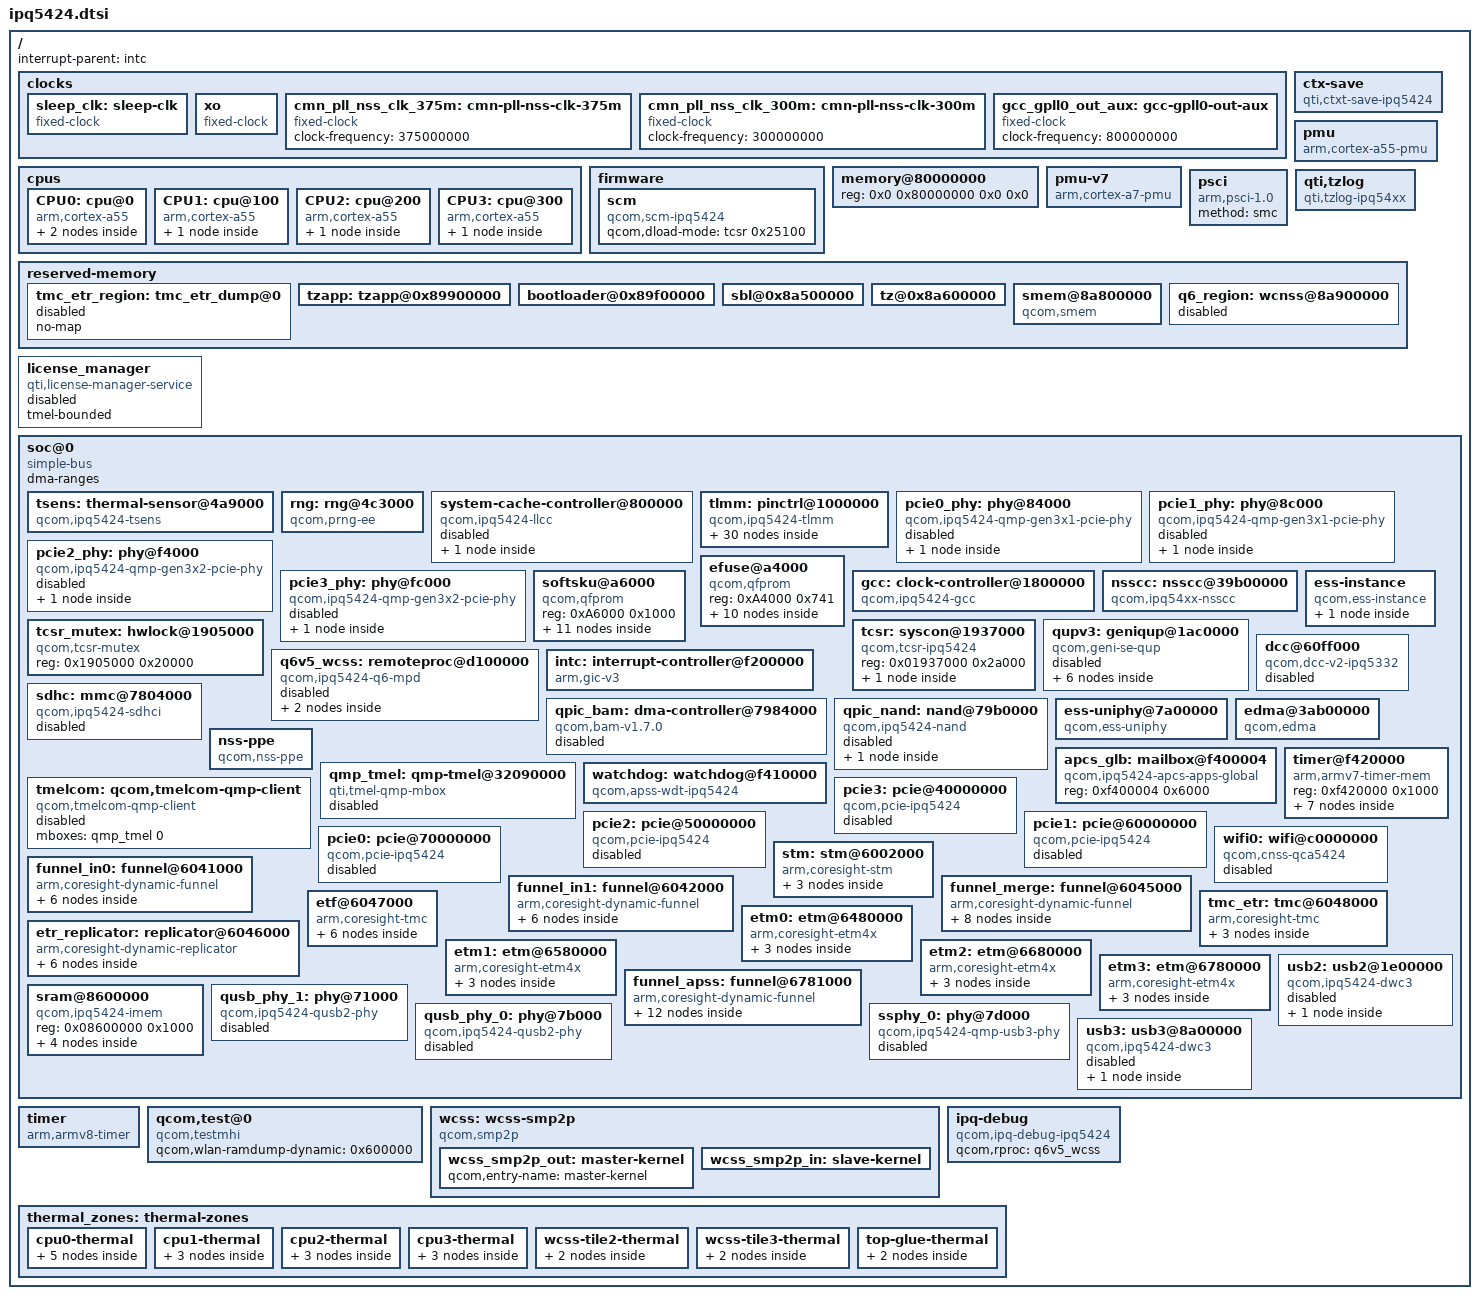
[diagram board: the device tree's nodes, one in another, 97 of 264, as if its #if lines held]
// SPDX-License-Identifier: (GPL-2.0+ OR BSD-3-Clause)
/*
 * IPQ5424 device tree source
 *
 * Copyright (c) 2020-2021 The Linux Foundation. All rights reserved.
 * Copyright (c) 2022-2024 Qualcomm Innovation Center, Inc. All rights reserved.
 */

#include <dt-bindings/interrupt-controller/arm-gic.h>
#include <dt-bindings/clock/qcom,ipq5424-gcc.h>
#include <dt-bindings/reset/qcom,ipq5424-gcc.h>
#include <dt-bindings/gpio/gpio.h>
#include <dt-bindings/clock/qcom,ipq5424-nsscc.h>
#include <dt-bindings/reset/qcom,ipq5424-nsscc.h>

/ {
	#address-cells = <2>;
	#size-cells = <2>;
	interrupt-parent = <&intc>;

	clocks {
		sleep_clk: sleep-clk {
			compatible = "fixed-clock";
			#clock-cells = <0>;
		};

		xo: xo {
			compatible = "fixed-clock";
			#clock-cells = <0>;
		};

		cmn_pll_nss_clk_375m: cmn-pll-nss-clk-375m {
			compatible = "fixed-clock";
			clock-frequency = <375000000>;
			#clock-cells = <0>;
		};

		cmn_pll_nss_clk_300m: cmn-pll-nss-clk-300m {
			compatible = "fixed-clock";
			clock-frequency = <300000000>;
			#clock-cells = <0>;
		};

		gcc_gpll0_out_aux: gcc-gpll0-out-aux {
			compatible = "fixed-clock";
			clock-frequency = <800000000>;
			#clock-cells = <0>;
		};
	};

	cpus: cpus {
		#address-cells = <1>;
		#size-cells = <0>;

		CPU0: cpu@0 {
			device_type = "cpu";
			compatible = "arm,cortex-a55";
			reg = <0x0>;
			enable-method = "psci";
			next-level-cache = <&L2_0>;
			L2_0: l2-cache {
				compatible = "cache";
				cache-level = <2>;
				cache-unified;
				next-level-cache = <&L3_0>;
				L3_0: l3-cache {
					compatible = "cache";
					cache-level = <3>;
					cache-unified;
				};
			};
		};

		CPU1: cpu@100 {
			device_type = "cpu";
			compatible = "arm,cortex-a55";
			enable-method = "psci";
			reg = <0x100>;
			next-level-cache = <&L2_100>;
			L2_100: l2-cache {
				compatible = "cache";
				cache-level = <2>;
				cache-unified;
				next-level-cache = <&L3_0>;
			};
		};

		CPU2: cpu@200 {
			device_type = "cpu";
			compatible = "arm,cortex-a55";
			enable-method = "psci";
			reg = <0x200>;
			next-level-cache = <&L2_200>;
			L2_200: l2-cache {
				compatible = "cache";
				cache-level = <2>;
				cache-unified;
				next-level-cache = <&L3_0>;
			};
		};

		CPU3: cpu@300 {
			device_type = "cpu";
			compatible = "arm,cortex-a55";
			enable-method = "psci";
			reg = <0x300>;
			next-level-cache = <&L2_300>;
			L2_300: l2-cache {
				compatible = "cache";
				cache-level = <2>;
				cache-unified;
				next-level-cache = <&L3_0>;
			};
		};
	};

	ctx-save {
		compatible = "qti,ctxt-save-ipq5424";
	};

	firmware {
		scm {
			compatible = "qcom,scm-ipq5424", "qcom,scm";
			qcom,dload-mode = <&tcsr 0x25100>;
		};
	};

	memory@80000000 {
		device_type = "memory";
		/* We expect the bootloader to fill in the size */
		reg = <0x0 0x80000000 0x0 0x0>;
	};

	pmu {
		compatible = "arm,cortex-a55-pmu";
		interrupts = <GIC_PPI 7 (GIC_CPU_MASK_SIMPLE(4) | IRQ_TYPE_LEVEL_HIGH)>;
	};

	pmu-v7 {
		compatible = "arm,cortex-a7-pmu";
		interrupts = <GIC_PPI 7 (GIC_CPU_MASK_SIMPLE(4) | IRQ_TYPE_LEVEL_HIGH)>;
	};

	psci {
		compatible = "arm,psci-1.0";
		method = "smc";
	};

	qti,tzlog {
		compatible = "qti,tzlog-ipq54xx";
		interrupts = <GIC_SPI 56 IRQ_TYPE_EDGE_RISING>;
		qti,tz-diag-buf-size = <0x3000>;
		qti,tz-ring-off = <7>;
		qti,tz-log-pos-info-off = <822>;
	};

	reserved-memory {
		#address-cells = <2>;
		#size-cells = <2>;
		ranges;

		tmc_etr_region: tmc_etr_dump@0 {
			no-map;
			status = "disabled";
		};

		tzapp: tzapp@0x89900000 {
		#if !defined(__IPQ_MEM_PROFILE_512_MB__) && !defined(__IPQ_MEM_PROFILE_256_MB__)
			reg = <0x0 0x89900000 0x0 0x600000>;
		#endif
			no-map;
		};

		bootloader@0x89f00000 {
			reg = <0x0 0x89f00000 0x0 0x600000>;
			no-map;
		};

		sbl@0x8a500000 {
			reg = <0x0 0x8a500000 0x0 0x100000>;
			no-map;
		};

		tz@0x8a600000 {
			reg = <0x0 0x8a600000 0x0 0x200000>;
			no-map;
		};

		smem@8a800000 {
			compatible = "qcom,smem";
			reg = <0x0 0x8a800000 0x0 0x100000>;
			no-map;

			hwlocks = <&tcsr_mutex 3>;
		};

		q6_region: wcnss@8a900000 {
			reg = <0x0 0x8a900000 0x0 0x02300000>;
			no-map;
			status = "disabled";
		};
	};

	license_manager: license_manager {
		compatible = "qti,license-manager-service";
		tmel-bounded;
		status = "disabled";
	};

	soc@0 {
		compatible = "simple-bus";
		#address-cells = <1>;
		#size-cells = <1>;
		ranges = <0 0 0 0xffffffff>;
		dma-ranges;

		tsens: thermal-sensor@4a9000 {
			compatible = "qcom,ipq5424-tsens";
			reg = <0x4a9000 0x1000>,
			      <0x4a8000 0x1000>;
			nvmem-cells = <&tsens_mode>, <&tsens_base0>, <&tsens_base1>,
				      <&s9>, <&s10>, <&s11>, <&s12>, <&s13>, <&s14>,
				      <&s15>;
			nvmem-cell-names = "mode", "base0", "base1", "s9",
					   "s10", "s11", "s12", "s13",
					   "s14", "s15";
			interrupts = <GIC_SPI 105 IRQ_TYPE_EDGE_RISING>;
			interrupt-names = "combined";
			#thermal-sensor-cells = <1>;
		};

		rng: rng@4c3000 {
			compatible = "qcom,prng-ee";
			reg = <0x004c3000 0x1000>;
			clocks = <&gcc GCC_PRNG_AHB_CLK>;
			clock-names = "core";
		};

		system-cache-controller@800000 {
			compatible = "qcom,ipq5424-llcc";
			reg = <0x00800000 0x200000>, <0x00800000 0x200000>;
			reg-names = "llcc_base", "llcc_broadcast_base";
			interrupts = <GIC_SPI 68 IRQ_TYPE_LEVEL_HIGH>;
			status = "disabled";

			llcc-perfmon {
				compatible = "qcom,llcc-perfmon";
			};
		};

		tlmm: pinctrl@1000000 {
			compatible = "qcom,ipq5424-tlmm";
			reg = <0x01000000 0x300000>;
			interrupts = <GIC_SPI 84 IRQ_TYPE_LEVEL_HIGH>;
			gpio-controller;
			#gpio-cells = <2>;
			gpio-ranges = <&tlmm 0 0 49>;
			interrupt-controller;
			#interrupt-cells = <2>;

			qup_i2c0_default: qup-i2c0-default-state {
				qup_i2c0_scl {
					pins = "gpio14";
					function = "i2c0_scl";
					drive-strength = <8>;
					bias-disable;
				};
				qup_i2c0_sda {
					pins = "gpio15";
					function = "i2c0_sda";
					drive-strength = <8>;
					bias-disable;
				};
			};

			qup_i2c1_default: qup-i2c1-default-state {
				qup_i2c1_scl {
					pins = "gpio16";
					function = "i2c1_scl";
					drive-strength = <8>;
					bias-disable;
				};
				qup_i2c1_sda {
					pins = "gpio17";
					function = "i2c1_sda";
					drive-strength = <8>;
					bias-disable;
				};
			};

			qup_uart0_default: qup-uart0-default-state {
				qup_uart0_tx: tx-pins {
					pins = "gpio43";
					function = "uart0_tx";
					drive-strength = <8>;
					bias-pull-up;
				};

				qup_uart0_rx: rx-pins {
					pins = "gpio44";
					function = "uart0_rx";
					drive-strength = <8>;
					bias-pull-up;
				};
			};

			qspi_default_state: qspi-default-state {
				qspi_clock {
					pins = "gpio5";
					function = "qspi_clk";
					drive-strength = <8>;
					bias-pull-down;
				};

				qspi_cs {
					pins = "gpio4";
					function = "qspi_cs";
					drive-strength = <8>;
					bias-pull-up;
				};

				qspi_data {
					pins = "gpio0", "gpio1", "gpio2", "gpio3";
					function = "qspi_data";
					drive-strength = <8>;
					bias-pull-down;
				};
			};

			sdc_default_state: sdc-default-state {
				clk-pins {
					pins = "gpio5";
					function = "sdc_clk";
					drive-strength = <8>;
					bias-disable;
				};

				cmd-pins {
					pins = "gpio4";
					function = "sdc_cmd";
					drive-strength = <8>;
					bias-pull-up;
				};

				data-pins {
					pins = "gpio0", "gpio1", "gpio2", "gpio3";
					function = "sdc_data";
					drive-strength = <8>;
					bias-pull-up;
				};
			};

			qup_spi0_default: qup-spi0-default-state {
				qup_spi0_clk {
					pins = "gpio6";
					function = "spi0_clk";
					drive-strength = <8>;
					bias-disable;
				};

				qup_spi0_cs {
					pins = "gpio7";
					function = "spi0_cs";
					drive-strength = <8>;
					bias-disable;
				};

				qup_spi0_miso {
					pins = "gpio8";
					function = "spi0_miso";
					drive-strength = <8>;
					bias-disable;
				};

				qup_spi0_mosi {
					pins = "gpio9";
					function = "spi0_mosi";
					drive-strength = <8>;
					bias-disable;
				};
			};

			pcie0_default_state: pcie0-default-state {
				perst-n-pins {
					pins = "gpio25";
					function = "gpio";
					drive-strength = <2>;
					bias-pull-down;
					output-low;
				};
			};

			pcie1_default_state: pcie1-default-state {
				perst-n-pins {
					pins = "gpio28";
					function = "gpio";
					drive-strength = <2>;
					bias-pull-down;
					output-low;
				};
			};

			pcie2_default_state: pcie2-default-state {
				perst-n-pins {
					pins = "gpio31";
					function = "gpio";
					drive-strength = <2>;
					bias-pull-down;
					output-low;
				};
			};

			pcie3_default_state: pcie3-default-state {
				perst-n-pins {
					pins = "gpio34";
					function = "gpio";
					drive-strength = <2>;
					bias-pull-down;
					output-low;
				};
			};
		};

		pcie0_phy: phy@84000 {
			compatible = "qcom,ipq5424-qmp-gen3x1-pcie-phy",
				     "qcom,ipq9574-qmp-gen3x1-pcie-phy";
			reg = <0x00084000 0x1bc>; /* Serdes PLL */
			#address-cells = <1>;
			#size-cells = <1>;
			ranges;

			clocks = <&gcc GCC_PCIE0_AUX_CLK>,
				 <&gcc GCC_PCIE0_AHB_CLK>,
				 <&gcc GCC_ANOC_PCIE0_1LANE_M_CLK>,
				 <&gcc GCC_CNOC_PCIE0_1LANE_S_CLK>;
			clock-names = "aux", "cfg_ahb", "anoc_lane", "snoc_lane";

			assigned-clocks = <&gcc GCC_PCIE0_AUX_CLK>,
					  <&gcc GCC_PCIE0_AHB_CLK>,
					  <&gcc GCC_ANOC_PCIE0_1LANE_M_CLK>,
					  <&gcc GCC_CNOC_PCIE0_1LANE_S_CLK>;
			assigned-clock-rates = <20000000>,
					       <100000000>,
					       <240000000>,
					       <240000000>;

			resets = <&gcc GCC_PCIE0_PHY_BCR>,
				 <&gcc GCC_PCIE0PHY_PHY_BCR>;
			reset-names = "phy", "common";

			status = "disabled";

			pcie0_lanes: phy@84200 {
				reg = <0x00084200 0x16c>, /* Serdes Tx0 */
				      <0x00084400 0x200>, /* Serdes Rx0 */
				      <0x00084800 0x1f0>, /* PCS: Lane0, COM, PCIE */
				      <0x00084c00 0x0f4>; /* pcs_misc */

				#phy-cells = <0>;

				clocks = <&gcc GCC_PCIE0_PIPE_CLK>;
				clock-names = "pipe0";
				clock-output-names = "gcc_pcie0_pipe_clk_src";
				#clock-cells = <0>;
			};
		};

		pcie1_phy: phy@8c000 {
			compatible = "qcom,ipq5424-qmp-gen3x1-pcie-phy",
				     "qcom,ipq9574-qmp-gen3x1-pcie-phy";
			reg = <0x0008c000 0x1bc>; /* Serdes PLL */
			#address-cells = <1>;
			#size-cells = <1>;
			ranges;

			clocks = <&gcc GCC_PCIE1_AUX_CLK>,
				 <&gcc GCC_PCIE1_AHB_CLK>,
				 <&gcc GCC_ANOC_PCIE1_1LANE_M_CLK>,
				 <&gcc GCC_CNOC_PCIE1_1LANE_S_CLK>;
			clock-names = "aux", "cfg_ahb", "anoc_lane", "snoc_lane";

			assigned-clocks = <&gcc GCC_PCIE1_AUX_CLK>,
					  <&gcc GCC_PCIE1_AHB_CLK>,
					  <&gcc GCC_ANOC_PCIE1_1LANE_M_CLK>,
					  <&gcc GCC_CNOC_PCIE1_1LANE_S_CLK>;
			assigned-clock-rates = <20000000>,
					       <100000000>,
					       <240000000>,
					       <240000000>;

			resets = <&gcc GCC_PCIE1_PHY_BCR>,
				 <&gcc GCC_PCIE1PHY_PHY_BCR>;
			reset-names = "phy", "common";

			status = "disabled";

			pcie1_lanes: phy@8c200 {
				reg = <0x0008c200 0x16c>, /* Serdes Tx0 */
				      <0x0008c400 0x200>, /* Serdes Rx0 */
				      <0x0008c800 0x1f0>, /* PCS: Lane0, COM, PCIE */
				      <0x0008cc00 0x0f4>; /* pcs_misc */

				#phy-cells = <0>;

				clocks = <&gcc GCC_PCIE1_PIPE_CLK>;
				clock-names = "pipe0";
				clock-output-names = "gcc_pcie1_pipe_clk_src";
				#clock-cells = <0>;
			};
		};

		pcie2_phy: phy@f4000 {
			compatible = "qcom,ipq5424-qmp-gen3x2-pcie-phy",
				     "qcom,ipq9574-qmp-gen3x2-pcie-phy";
			reg = <0x000f4000 0x1bc>; /* Serdes PLL */
			#address-cells = <1>;
			#size-cells = <1>;
			ranges;

			clocks = <&gcc GCC_PCIE2_AUX_CLK>,
				 <&gcc GCC_PCIE2_AHB_CLK>,
				 <&gcc GCC_ANOC_PCIE2_2LANE_M_CLK>,
				 <&gcc GCC_CNOC_PCIE2_2LANE_S_CLK>;
			clock-names = "aux", "cfg_ahb", "anoc_lane", "snoc_lane";

			assigned-clocks = <&gcc GCC_PCIE2_AUX_CLK>,
					  <&gcc GCC_PCIE2_AHB_CLK>,
					  <&gcc GCC_ANOC_PCIE2_2LANE_M_CLK>,
					  <&gcc GCC_CNOC_PCIE2_2LANE_S_CLK>;
			assigned-clock-rates = <20000000>,
					       <100000000>,
					       <266666666>,
					       <240000000>;

			resets = <&gcc GCC_PCIE2_PHY_BCR>,
				 <&gcc GCC_PCIE2PHY_PHY_BCR>;
			reset-names = "phy", "common";

			status = "disabled";

			pcie2_lanes: phy@f4200 {
				reg = <0x000f4200 0x16c>, /* Serdes Tx0 */
				      <0x000f4400 0x200>, /* Serdes Rx0 */
				      <0x000f5000 0x1f0>, /* PCS: Lane0, COM, PCIE */
				      <0x000f4600 0x16c>, /* Serdes Tx1 */
				      <0x000f4800 0x200>, /* Serdes Rx1 */
				      <0x000f5400 0x0f8>; /* pcs_misc */

				#phy-cells = <0>;

				clocks = <&gcc GCC_PCIE2_PIPE_CLK>;
				clock-names = "pipe0";
				clock-output-names = "gcc_pcie2_pipe_clk_src";
				#clock-cells = <0>;
			};
		};

		pcie3_phy: phy@fc000 {
			compatible = "qcom,ipq5424-qmp-gen3x2-pcie-phy",
				     "qcom,ipq9574-qmp-gen3x2-pcie-phy";
			reg = <0x000fc000 0x1bc>; /* Serdes PLL */
			#address-cells = <1>;
			#size-cells = <1>;
			ranges;

			clocks = <&gcc GCC_PCIE3_AUX_CLK>,
				 <&gcc GCC_PCIE3_AHB_CLK>,
				 <&gcc GCC_ANOC_PCIE3_2LANE_M_CLK>,
				 <&gcc GCC_CNOC_PCIE3_2LANE_S_CLK>;
			clock-names = "aux", "cfg_ahb", "anoc_lane", "snoc_lane";

			assigned-clocks = <&gcc GCC_PCIE3_AUX_CLK>,
					  <&gcc GCC_PCIE3_AHB_CLK>,
					  <&gcc GCC_ANOC_PCIE3_2LANE_M_CLK>,
					  <&gcc GCC_CNOC_PCIE3_2LANE_S_CLK>;
			assigned-clock-rates = <20000000>,
					       <100000000>,
					       <266666666>,
					       <240000000>;

			resets = <&gcc GCC_PCIE3_PHY_BCR>,
				 <&gcc GCC_PCIE3PHY_PHY_BCR>;
			reset-names = "phy", "common";

			status = "disabled";

			pcie3_lanes: phy@fc200 {
				reg = <0x000fc200 0x16c>, /* Serdes Tx0 */
				      <0x000fc400 0x200>, /* Serdes Rx0 */
				      <0x000fd000 0x1f0>, /* PCS: Lane0, COM, PCIE */
				      <0x000fc600 0x16c>, /* Serdes Tx1 */
				      <0x000fc800 0x200>, /* Serdes Rx1 */
				      <0x000fd400 0x0f8>; /* pcs_misc */

				#phy-cells = <0>;

				clocks = <&gcc GCC_PCIE3_PIPE_CLK>;
				clock-names = "pipe0";
				clock-output-names = "gcc_pcie3_pipe_clk_src";
				#clock-cells = <0>;
			};
		};

		efuse@a4000 {
			compatible = "qcom,qfprom";
			reg = <0xA4000 0x741>;
			#address-cells = <1>;
			#size-cells = <1>;

			s9: s9@3dc {
				reg = <0x3dc 0x1>;
				bits = <4 4>;
			};

			s10: s10@3dd {
				reg = <0x3dd 0x1>;
				bits = <0 4>;
			};

			s11: s11@3dd {
				reg = <0x3dd 0x1>;
				bits = <4 4>;
			};

			s12: s12@3de {
				reg = <0x3de 0x1>;
				bits = <0 4>;
			};

			s13: s13@3de {
				reg = <0x3de 0x1>;
				bits = <4 4>;
			};

			s14: s14@3e5 {
				reg = <0x3e5 0x2>;
				bits = <7 4>;
			};

			s15: s15@3e6 {
				reg = <0x3e6 0x1>;
				bits = <3 4>;
			};

			tsens_mode: mode@419 {
				reg = <0x419 0x1>;
				bits = <0 3>;
			};

			tsens_base0: base0@419 {
				reg = <0x419 0x2>;
				bits = <3 10>;
			};

			tsens_base1: base1@41a {
				reg = <0x41a 0x2>;
				bits = <5 10>;
			};
		};

		softsku@a6000 {
			compatible = "qcom,qfprom";
			reg = <0xA6000 0x1000>;
			#address-cells = <1>;
			#size-cells = <1>;

			apss_cpu_freq: apss_cpu_freq@234 {
				reg = <0x234 0x1>;
				bits = <0 8>;
			};

			ddr_space_limit: ddr_space_limit@23c {
				reg = <0x23c 0x1>;
				bits = <0 1>;
			};

			pcie0_disable: pcie0_disable@244 {
				reg = <0x244 0x1>;
				bits = <0 1>;
			};

			pcie1_disable: pcie1_disable@24c {
				reg = <0x24c 0x1>;
				bits = <0 1>;
			};

			pcie2_disable: pcie2_disable@254 {
				reg = <0x254 0x1>;
				bits = <0 1>;
			};

			pcie3_disable: pcie3_disable@25c {
				reg = <0x25c 0x1>;
				bits = <0 1>;
			};

			uniphy0_disable: uniphy0_disable@264 {
				reg = <0x264 0x1>;
				bits = <0 1>;
			};

			uniphy1_disable: uniphy1_disable@26c {
				reg = <0x26c 0x1>;
				bits = <0 1>;
			};

			uniphy2_disable: uniphy2_disable@274 {
				reg = <0x274 0x1>;
				bits = <0 1>;
			};

			nss_disable: nss_disable@284 {
				reg = <0x284 0x1>;
				bits = <0 1>;
			};

			usb_disable: usb_disable@28c {
				reg = <0x28c 0x1>;
				bits = <0 1>;
			};
		};

		gcc: clock-controller@1800000 {
			compatible = "qcom,ipq5424-gcc";
			reg = <0x01800000 0x40000>;
			clocks = <&xo>,
				 <&sleep_clk>;
			#clock-cells = <1>;
			#reset-cells = <1>;
			#power-domain-cells = <1>;
                };

		nsscc: nsscc@39b00000{
			compatible = "qcom,ipq54xx-nsscc";
			reg = <0x39b00000 0x80000>;
			clocks = <&xo>,
				<&cmn_pll_nss_clk_375m>,
				<&cmn_pll_nss_clk_300m>,
				<&gcc_gpll0_out_aux>;
			clock-names = "xo",
					"cmn_pll_nss_clk_375m",
					"cmn_pll_nss_clk_300m",
					"gcc_gpll0_out_aux";
			#clock-cells = <0x1>;
			#reset-cells = <0x1>;
		};

		tcsr_mutex: hwlock@1905000 {
			compatible = "qcom,tcsr-mutex";
			reg = <0x1905000 0x20000>;
			#hwlock-cells = <1>;
		};

		tcsr: syscon@1937000 {
			compatible = "qcom,tcsr-ipq5424", "syscon", "simple-mfd";
			reg = <0x01937000 0x2a000>;
			#address-cells = <1>;
			#size-cells = <1>;
			ranges = <0x0 0x01937000 0x2a000>;

			 pwm: pwm@a010 {
				compatible = "qcom,ipq9574-pwm";
				reg = <0xa010 0x20>;
				clocks = <&gcc GCC_ADSS_PWM_CLK>;
				assigned-clocks = <&gcc GCC_ADSS_PWM_CLK>;
				assigned-clock-rates = <100000000>;
				#pwm-cells = <2>;
				status = "disabled";
			};
		};

		qupv3: geniqup@1ac0000 {
			compatible = "qcom,geni-se-qup";
			reg = <0x01ac0000 0x2000>;
			clocks = <&gcc GCC_QUPV3_AHB_MST_CLK>,
				 <&gcc GCC_QUPV3_AHB_SLV_CLK>;
			clock-names = "m-ahb", "s-ahb";
			ranges;

			status = "disabled";

			uart0: serial@1a80000 {
				compatible = "qcom,geni-debug-uart";
				reg = <0x01a80000 0x4000>;
				clocks = <&gcc GCC_QUPV3_UART0_CLK>;
				clock-names = "se";
				interrupts = <GIC_SPI 339 IRQ_TYPE_LEVEL_HIGH>;
				status = "disabled";
			};

			uart1: serial@1a84000 {
				compatible = "qcom,geni-uart";
				reg = <0x01a84000 0x4000>;
				clocks = <&gcc GCC_QUPV3_UART1_CLK>;
				clock-names = "se";
				interrupts = <GIC_SPI 340 IRQ_TYPE_LEVEL_HIGH>;
				status = "disabled";
			};

			i2c0: i2c@1a88000 {
				compatible = "qcom,geni-i2c";
				reg = <0x1a88000 0x4000>;
				clocks = <&gcc GCC_QUPV3_I2C0_CLK>;
				clock-names = "se";
				clock-frequency = <400000>;
				interrupts = <GIC_SPI 341 IRQ_TYPE_LEVEL_HIGH>;
				status = "disabled";
			};

			i2c1: i2c@1a8c000 {
				compatible = "qcom,geni-i2c";
				reg = <0x1a8c000 0x4000>;
				clocks = <&gcc GCC_QUPV3_I2C1_CLK>;
				clock-names = "se";
				clock-frequency = <400000>;
				interrupts = <GIC_SPI 342 IRQ_TYPE_LEVEL_HIGH>;
				status = "disabled";
			};

			spi0: spi@1a90000 {
				compatible = "qcom,geni-spi";
				reg = <0x1a90000 0x4000>;
				clocks = <&gcc GCC_QUPV3_SPI0_CLK>;
				clock-names = "se";
				interrupts = <GIC_SPI 343 IRQ_TYPE_LEVEL_HIGH>;
				status = "disabled";
			};

			spi1: spi@1a94000 {
				compatible = "qcom,geni-spi";
				reg = <0x1a94000 0x4000>;
				clocks = <&gcc GCC_QUPV3_SPI1_CLK>;
				clock-names = "se";
				interrupts = <GIC_SPI 344 IRQ_TYPE_LEVEL_HIGH>;
				status = "disabled";
			};
		};

		q6v5_wcss: remoteproc@d100000 {
			compatible = "qcom,ipq5424-q6-mpd";
			#address-cells = <1>;
			#size-cells = <1>;
			ranges;
#ifdef __QCOM_NON_SECURE_PIL__
			reg = <0xd100000 0x4040>;
			reg-names = "qdsp6";
			resets = <&gcc GCC_WCSS_Q6_BCR>,
				 <&gcc GCC_WAPSS_BCR>;
			reset-names = "wcss_q6_reset",
				      "wapss_reset";
			clocks = <&gcc GCC_Q6_TSCTR_1TO2_CLK>,
				 <&gcc GCC_Q6SS_TRIG_CLK>,
				 <&gcc GCC_Q6_AHB_S_CLK>,
				 <&gcc GCC_Q6_AHB_CLK>,
				 <&gcc GCC_Q6SS_ATBM_CLK>,
				 <&gcc GCC_Q6_AXIM_CLK>,
				 <&gcc GCC_Q6SS_BOOT_CLK>,
				 <&gcc GCC_Q6SS_PCLKDBG_CLK>,
				 <&gcc GCC_WCSS_ECAHB_CLK>,
				 <&gcc GCC_CNOC_WCSS_AHB_CLK>;

			clock-names = "q6_tsctr_1to2",
				      "q6ss_trig",
				      "q6_ahb_s",
				      "q6_ahb",
				      "q6ss_atbm",
				      "q6_axim",
				      "q6ss_boot",
				      "q6ss_pclkdbg",
				      "wcss_ecahb",
				      "cnoc_wcss_ahb";
			qcom,q6-tcsr-regs = <&tcsr 0x6204 0x1B000>;
#endif
			firmware = "IPQ5424/q6_fw0.mdt";
			interrupts-extended = <&intc GIC_SPI 508 IRQ_TYPE_EDGE_RISING>,
					      <&wcss_smp2p_in 0 0>,
					      <&wcss_smp2p_in 1 0>,
					      <&wcss_smp2p_in 2 0>,
					      <&wcss_smp2p_in 3 0>;
			interrupt-names = "wdog",
					  "fatal",
					  "ready",
					  "handover",
					  "stop-ack";
			qcom,smem-states = <&wcss_smp2p_out 0>,
					   <&wcss_smp2p_out 1>;
			qcom,smem-state-names = "shutdown",
						"stop";

			memory-region = <&q6_region>;
			qcom,bootargs_smem = <507>;
			qcom,bootargs_version = <2>;
			qcom,userpd-bootargs;
			status = "disabled";

			glink-edge {
				interrupts = <GIC_SPI 500 IRQ_TYPE_EDGE_RISING>;
				label = "rtr";
				qcom,remote-pid = <1>;
				mboxes = <&apcs_glb 8>;
			};

			q6_wcss_pd1: remoteproc_pd1 {
				compatible = "qcom,ipq5424-wcss-ahb-mpd";
				firmware = "IPQ5424/q6_fw1.mdt";
				m3_firmware = "IPQ5424/iu_fw.mdt";
				interrupts-extended = <&wcss_smp2p_in 8 0>,
						      <&wcss_smp2p_in 9 0>,
						      <&wcss_smp2p_in 12 0>,
						      <&wcss_smp2p_in 11 0>;
				interrupt-names = "fatal",
						  "ready",
						  "spawn-ack",
						  "stop-ack";

				qcom,smem-states = <&wcss_smp2p_out 8>,
						   <&wcss_smp2p_out 9>,
						   <&wcss_smp2p_out 10>;
				qcom,smem-state-names = "shutdown",
							"stop",
							"spawn";
			};
		};

		intc: interrupt-controller@f200000 {
			compatible = "arm,gic-v3";
			reg = <0xf200000 0x10000>, /* GICD */
			      <0xf240000 0x80000>; /* GICR * 4 regions */
			#interrupt-cells = <0x3>;
			interrupt-controller;
			#redistributor-regions = <1>;
			redistributor-stride = <0x0 0x20000>;
			interrupts = <GIC_PPI 9 IRQ_TYPE_LEVEL_HIGH>;
			mbi-ranges = <672 128>;
			msi-controller;
		};

		ess-instance {
			compatible = "qcom,ess-instance";
			ess-switch@3a000000 {
				compatible = "qcom,ess-switch-ipq54xx";
				switch_access_mode = "local bus";
				reg = <0x3a000000 0x1000000>;
				clocks = <&gcc GCC_CMN_12GPLL_AHB_CLK>,
					<&gcc GCC_CMN_12GPLL_SYS_CLK>,
					<&gcc GCC_UNIPHY0_AHB_CLK>,
					<&gcc GCC_UNIPHY0_SYS_CLK>,
					<&gcc GCC_UNIPHY1_AHB_CLK>,
					<&gcc GCC_UNIPHY1_SYS_CLK>,
					<&gcc GCC_UNIPHY2_AHB_CLK>,
					<&gcc GCC_UNIPHY2_SYS_CLK>,
					<&gcc GCC_NSSNOC_NSSCC_CLK>,
					<&gcc GCC_NSSCC_CLK>,
					<&gcc GCC_NSSNOC_SNOC_1_CLK>,
					<&gcc GCC_NSSNOC_SNOC_CLK>,
					<&gcc GCC_IM_SLEEP_CLK>,
					<&nsscc NSS_CC_PORT1_MAC_CLK>,
					<&nsscc NSS_CC_PORT2_MAC_CLK>,
					<&nsscc NSS_CC_PORT3_MAC_CLK>,
					<&nsscc NSS_CC_PPE_SWITCH_CLK>,
					<&nsscc NSS_CC_PPE_SWITCH_CFG_CLK>,
					<&nsscc NSS_CC_NSSNOC_PPE_CLK>,
					<&nsscc NSS_CC_NSSNOC_PPE_CFG_CLK>,
					<&nsscc NSS_CC_PPE_EDMA_CLK>,
					<&nsscc NSS_CC_PPE_EDMA_CFG_CLK>,
					<&nsscc NSS_CC_PPE_SWITCH_IPE_CLK>,
					<&nsscc NSS_CC_PPE_SWITCH_BTQ_CLK>,
					<&nsscc NSS_CC_PORT1_RX_CLK>,
					<&nsscc NSS_CC_PORT1_TX_CLK>,
					<&nsscc NSS_CC_PORT2_RX_CLK>,
					<&nsscc NSS_CC_PORT2_TX_CLK>,
					<&nsscc NSS_CC_PORT3_RX_CLK>,
					<&nsscc NSS_CC_PORT3_TX_CLK>,
					<&nsscc NSS_CC_UNIPHY_PORT1_RX_CLK>,
					<&nsscc NSS_CC_UNIPHY_PORT1_TX_CLK>,
					<&nsscc NSS_CC_UNIPHY_PORT2_RX_CLK>,
					<&nsscc NSS_CC_UNIPHY_PORT2_TX_CLK>,
					<&nsscc NSS_CC_UNIPHY_PORT3_RX_CLK>,
					<&nsscc NSS_CC_UNIPHY_PORT3_TX_CLK>;
				clock-names = "cmn_ahb_clk",
					"cmn_sys_clk",
					"uniphy0_ahb_clk",
					"uniphy0_sys_clk",
					"uniphy1_ahb_clk",
					"uniphy1_sys_clk",
					"uniphy2_ahb_clk",
					"uniphy2_sys_clk",
					"gcc_nssnoc_nsscc_clk",
					"gcc_nsscc_clk",
					"gcc_nssnoc_snoc_1_clk",
					"gcc_nssnoc_snoc_clk",
					"gcc_im_sleep_clk",
					"port1_mac_clk",
					"port2_mac_clk",
					"port3_mac_clk",
					"nss_ppe_clk",
					"nss_ppe_cfg_clk",
					"nssnoc_ppe_clk",
					"nssnoc_ppe_cfg_clk",
					"nss_edma_clk",
					"nss_edma_cfg_clk",
					"nss_ppe_ipe_clk",
					"nss_ppe_btq_clk",
					"nss_port1_rx_clk",
					"nss_port1_tx_clk",
					"nss_port2_rx_clk",
					"nss_port2_tx_clk",
					"nss_port3_rx_clk",
					"nss_port3_tx_clk",
					"uniphy0_port1_rx_clk",
					"uniphy0_port1_tx_clk",
					"uniphy1_port5_rx_clk",
					"uniphy1_port5_tx_clk",
					"uniphy2_port6_rx_clk",
					"uniphy2_port6_tx_clk";
				resets = <&nsscc NSS_CC_PPE_BCR>,
					<&gcc GCC_UNIPHY0_BCR>,
					<&gcc GCC_UNIPHY1_BCR>,
					<&gcc GCC_UNIPHY2_BCR>,
					<&gcc GCC_UNIPHY0_AHB_ARES>,
					<&gcc GCC_UNIPHY1_AHB_ARES>,
					<&gcc GCC_UNIPHY2_AHB_ARES>,
					<&gcc GCC_UNIPHY0_SYS_ARES>,
					<&gcc GCC_UNIPHY1_SYS_ARES>,
					<&gcc GCC_UNIPHY2_SYS_ARES>,
					<&gcc GCC_UNIPHY0_XPCS_ARES>,
					<&gcc GCC_UNIPHY1_XPCS_ARES>,
					<&gcc GCC_UNIPHY2_XPCS_ARES>,
					<&nsscc NSS_CC_UNIPHY_PORT1_RX_CLK_ARES>,
					<&nsscc NSS_CC_UNIPHY_PORT1_TX_CLK_ARES>,
					<&nsscc NSS_CC_UNIPHY_PORT2_RX_CLK_ARES>,
					<&nsscc NSS_CC_UNIPHY_PORT2_TX_CLK_ARES>,
					<&nsscc NSS_CC_UNIPHY_PORT3_RX_CLK_ARES>,
					<&nsscc NSS_CC_UNIPHY_PORT3_TX_CLK_ARES>,
					<&nsscc NSS_CC_PORT1_RX_CLK_ARES>,
					<&nsscc NSS_CC_PORT1_TX_CLK_ARES>,
					<&nsscc NSS_CC_PORT2_RX_CLK_ARES>,
					<&nsscc NSS_CC_PORT2_TX_CLK_ARES>,
					<&nsscc NSS_CC_PORT3_RX_CLK_ARES>,
					<&nsscc NSS_CC_PORT3_TX_CLK_ARES>,
					<&nsscc NSS_CC_PORT1_MAC_CLK_ARES>,
					<&nsscc NSS_CC_PORT2_MAC_CLK_ARES>,
					<&nsscc NSS_CC_PORT3_MAC_CLK_ARES>;
				reset-names = "ppe_rst",
					"uniphy0_soft_rst",
					"uniphy1_soft_rst",
					"uniphy2_soft_rst",
					"uniphy0_ahb_rst",
					"uniphy1_ahb_rst",
					"uniphy2_ahb_rst",
					"uniphy0_sys_rst",
					"uniphy1_sys_rst",
					"uniphy2_sys_rst",
					"uniphy0_xpcs_rst",
					"uniphy1_xpcs_rst",
					"uniphy2_xpcs_rst",
					"uniphy_port1_rx_rst",
					"uniphy_port1_tx_rst",
					"uniphy_port2_rx_rst",
					"uniphy_port2_tx_rst",
					"uniphy_port3_rx_rst",
					"uniphy_port3_tx_rst",
					"nss_port1_rx_rst",
					"nss_port1_tx_rst",
					"nss_port2_rx_rst",
					"nss_port2_tx_rst",
					"nss_port3_rx_rst",
					"nss_port3_tx_rst",
					"nss_port1_mac_rst",
					"nss_port2_mac_rst",
					"nss_port3_mac_rst";

			};
		};

		dcc@60ff000 {
			compatible = "qcom,dcc-v2-ipq5332";
			reg = <0x60ff000 0x1000>,
			      <0x6084000 0x4000>;
			reg-names = "dcc-base", "dcc-ram-base";
			dcc-ram-offset = <0x4000>;
			status = "disabled";
		};

		sdhc: mmc@7804000 {
			compatible = "qcom,ipq5424-sdhci", "qcom,sdhci-msm-v5";
			reg = <0x07804000 0x1000>, <0x07805000 0x1000>,
			      <0x07808000 0x2000>;
			reg-names = "hc", "cqhci", "ice";

			interrupts = <GIC_SPI 116 IRQ_TYPE_LEVEL_HIGH>,
				     <GIC_SPI 119 IRQ_TYPE_LEVEL_HIGH>;
			interrupt-names = "hc_irq", "pwr_irq";

			clocks = <&gcc GCC_SDCC1_AHB_CLK>,
				 <&gcc GCC_SDCC1_APPS_CLK>,
				 <&xo>,
				 <&gcc GCC_SDCC1_ICE_CORE_CLK>;
			clock-names = "iface", "core", "xo", "ice";

			pinctrl-0 = <&sdc_default_state>;
			pinctrl-names = "default";
			supports-cqe;

			status = "disabled";
		};

		qpic_bam: dma-controller@7984000 {
			compatible = "qcom,bam-v1.7.0";
			reg = <0x7984000 0x1c000>;
			interrupts = <GIC_SPI 109 IRQ_TYPE_LEVEL_HIGH>;
			clocks = <&gcc GCC_QPIC_AHB_CLK>;
			clock-names = "bam_clk";
			#dma-cells = <1>;
			qcom,ee = <0>;
			qcom,bam-lite;
			status = "disabled";
		};

		qpic_nand: nand@79b0000 {
			compatible = "qcom,ipq5424-nand";
			reg = <0x79b0000 0x10000>;
			#address-cells = <1>;
			#size-cells = <0>;
			clocks = <&gcc GCC_QPIC_CLK>,
				 <&gcc GCC_QPIC_AHB_CLK>,
				 <&gcc GCC_QPIC_IO_MACRO_CLK>;
			clock-names = "core", "aon", "io_macro";

			dmas = <&qpic_bam 0>,
			       <&qpic_bam 1>,
			       <&qpic_bam 2>,
			       <&qpic_bam 3>;
			dma-names = "tx", "rx", "cmd", "sts";

			qcom,io_macro_max_clk = <320000000>;
			qcom,io_macro_clk_rates = <24000000 100000000 200000000 \
						   320000000>;

			pinctrl-0 = <&qspi_default_state>;
			pinctrl-names = "default";

			status = "disabled";
			nandcs@0 {
				reg = <0>;
				#address-cells = <1>;
				#size-cells = <1>;

				nand-ecc-strength = <8>;
				nand-ecc-step-size = <512>;
				nand-bus-width = <8>;
			};
		};

		ess-uniphy@7a00000 {
			compatible = "qcom,ess-uniphy";
			reg = <0x7a00000 0x30000>;
			uniphy_access_mode = "local bus";
		};

		edma@3ab00000 {
			compatible = "qcom,edma";
			reg = <0x3ab00000 0xef800>;
			reg-names = "edma-reg-base";
			reset-names = "edma_rst";
			clocks = <&nsscc NSS_CC_NSS_CSR_CLK>,
				<&nsscc NSS_CC_NSSNOC_NSS_CSR_CLK>,
				<&nsscc NSS_CC_CE_APB_CLK>,
				<&nsscc NSS_CC_CE_AXI_CLK>,
				<&nsscc NSS_CC_NSSNOC_CE_APB_CLK>,
				<&nsscc NSS_CC_NSSNOC_CE_AXI_CLK>,
				<&nsscc NSS_CC_PPE_EDMA_CLK>,
				<&gcc GCC_NSS_TS_CLK>,
				<&gcc GCC_NSSCC_CLK>,
				<&gcc GCC_NSSCFG_CLK>,
				<&gcc GCC_NSSNOC_ATB_CLK>,
				<&gcc GCC_NSSNOC_NSSCC_CLK>,
				<&gcc GCC_NSSNOC_PCNOC_1_CLK>,
				<&gcc GCC_NSSNOC_QOSGEN_REF_CLK>,
				<&gcc GCC_NSSNOC_SNOC_1_CLK>,
				<&gcc GCC_NSSNOC_SNOC_CLK>,
				<&gcc GCC_NSSNOC_TIMEOUT_REF_CLK>,
				<&gcc GCC_NSSNOC_XO_DCD_CLK>;
			clock-names = "nss-csr-clk", "nss-nssnoc-csr-clk", "nss-ce-apb-clk",
				"nss-ce-axi-clk", "nss-nssnoc-ce-apb-clk", "nss-nssnoc-ce-axi-clk", "nss-edma-clk",
				"nss-ts-clk", "nss-nsscc-clk", "nss-nsscfg-clk", "nss-nssnoc-atb-clk",
				"nss-nssnoc-nsscc-clk", "nss-nssnoc-pcnoc-1-clk", "nss-nssnoc-qosgen-ref-clk",
				"nss-nssnoc-snoc-1-clk", "nss-nssnoc-snoc-clk", "nss-nssnoc-timeout-ref-clk",
				"nss-nssnoc-xo-dcd-clk";
                };

		nss-ppe {
			compatible = "qcom,nss-ppe";
		};

		apcs_glb: mailbox@f400004 {
			compatible = "qcom,ipq5424-apcs-apps-global",
				     "qcom,ipq6018-apcs-apps-global";
			reg = <0xf400004 0x6000>;
			#clock-cells = <1>;
			#mbox-cells = <1>;
		};

		qmp_tmel: qmp-tmel@32090000 {
			compatible = "qti,tmel-qmp-mbox";
			reg = <0x32090000 0x20>,
			      <0x32091000 0x20>;
			reg-names = "mcore", "ucore";

			interrupts = <GIC_SPI 126 IRQ_TYPE_EDGE_RISING>;
			max_pkt_size = <0x18>;

			mboxes = <&apcs_glb 20>;
			qti,early-boot;
			#mbox-cells = <1>;
			status = "disabled";
		};

		tmelcom: qcom,tmelcom-qmp-client {
			compatible = "qcom,tmelcom-qmp-client";
			mboxes = <&qmp_tmel 0>;
			status = "disabled";
		};

		watchdog: watchdog@f410000 {
			compatible = "qcom,apss-wdt-ipq5424", "qcom,kpss-wdt";
			reg = <0xf410000 0x1000>;
			interrupts = <GIC_SPI 0 IRQ_TYPE_EDGE_RISING>;
			clocks = <&sleep_clk>;
			timeout-sec = <30>;
		};

		timer@f420000 {
			compatible = "arm,armv7-timer-mem";
			reg = <0xf420000 0x1000>;
			#address-cells = <1>;
			#size-cells = <1>;
			ranges;

			frame@f421000 {
				reg = <0xf421000 0x1000>,
				      <0xf422000 0x1000>;
				interrupts = <GIC_SPI 8 IRQ_TYPE_LEVEL_HIGH>,
					     <GIC_SPI 6 IRQ_TYPE_LEVEL_HIGH>;
				frame-number = <0>;
			};

			frame@f423000 {
				reg = <0xf423000 0x1000>;
				interrupts = <GIC_SPI 9 IRQ_TYPE_LEVEL_HIGH>;
				frame-number = <1>;
				status = "disabled";
			};

			frame@f425000 {
				reg = <0xf425000 0x1000>,
				      <0xf426000 0x1000>;
				interrupts = <GIC_SPI 10 IRQ_TYPE_LEVEL_HIGH>;
				frame-number = <2>;
				status = "disabled";
			};

			frame@f427000 {
				reg = <0xf427000 0x1000>;
				interrupts = <GIC_SPI 11 IRQ_TYPE_LEVEL_HIGH>;
				frame-number = <3>;
				status = "disabled";
			};

			frame@f429000 {
				reg = <0xf429000 0x1000>;
				interrupts = <GIC_SPI 12 IRQ_TYPE_LEVEL_HIGH>;
				frame-number = <4>;
				status = "disabled";
			};

			frame@f42b000 {
				reg = <0xf42b000 0x1000>;
				interrupts = <GIC_SPI 13 IRQ_TYPE_LEVEL_HIGH>;
				frame-number = <5>;
				status = "disabled";
			};

			frame@f42d000 {
				reg = <0xf42d000 0x1000>;
				interrupts = <GIC_SPI 14 IRQ_TYPE_LEVEL_HIGH>;
				frame-number = <6>;
				status = "disabled";
			};
		};

		/* 2L controller */
		pcie3: pcie@40000000 {
			compatible = "qcom,pcie-ipq5424";
			reg =  <0x40000000 0xf1d>,
			       <0x40000f20 0xa8>,
			       <0x40001000 0x1000>,
			       <0xf8000 0x3000>,
			       <0x40100000 0x1000>;
			reg-names = "dbi", "elbi", "atu", "parf", "config";
			device_type = "pci";
			linux,pci-domain = <3>;
			bus-range = <0x00 0xff>;
			num-lanes = <2>;
			#address-cells = <3>;
			#size-cells = <2>;

			ranges = <0x81000000 0 0x40200000 0x40200000 0 0x00100000>,   /* downstream I/O */
				 <0x82000000 0 0x40300000 0x40300000 0 0x0fd00000>; /* non-prefetchable memory */

			#interrupt-cells = <1>;
			interrupt-map-mask = <0 0 0 0x7>;
			interrupt-map = <0 0 0 1 &intc 0 479 IRQ_TYPE_LEVEL_HIGH>, /* int_a */
					<0 0 0 2 &intc 0 480 IRQ_TYPE_LEVEL_HIGH>, /* int_b */
					<0 0 0 3 &intc 0 481 IRQ_TYPE_LEVEL_HIGH>, /* int_c */
					<0 0 0 4 &intc 0 482 IRQ_TYPE_LEVEL_HIGH>; /* int_d */

			interrupts = <GIC_SPI 478 IRQ_TYPE_LEVEL_HIGH>;
			interrupt-names = "global_irq";

			clocks = <&gcc GCC_PCIE3_AXI_M_CLK>,
				 <&gcc GCC_PCIE3_AXI_S_CLK>,
				 <&gcc GCC_PCIE3_AHB_CLK>,
				 <&gcc GCC_PCIE3_AUX_CLK>,
				 <&gcc GCC_PCIE3_AXI_S_BRIDGE_CLK>,
				 <&gcc GCC_PCIE3_RCHNG_CLK>;

			clock-names = "axi_m",
				      "axi_s",
				      "ahb",
				      "aux",
				      "axi_bridge",
				      "rchng";

			assigned-clocks = <&gcc GCC_PCIE3_AHB_CLK>,
					<&gcc GCC_PCIE3_AUX_CLK>,
					<&gcc GCC_PCIE3_AXI_M_CLK>,
					<&gcc GCC_PCIE3_AXI_S_BRIDGE_CLK>,
					<&gcc GCC_PCIE3_AXI_S_CLK>,
					<&gcc GCC_PCIE3_RCHNG_CLK>;

			assigned-clock-rates = <100000000>,
						<20000000>,
						<266666666>,
						<240000000>,
						<240000000>,
						<100000000>;

			resets = <&gcc GCC_PCIE3_PIPE_ARES>,
				 <&gcc GCC_PCIE3_CORE_STICKY_RESET>,
				 <&gcc GCC_PCIE3_AXI_M_ARES>,
				 <&gcc GCC_PCIE3_AXI_S_ARES>,
				 <&gcc GCC_PCIE3_AXI_M_STICKY_RESET>,
				 <&gcc GCC_PCIE3_AXI_S_STICKY_RESET>,
				 <&gcc GCC_PCIE3_AHB_ARES>,
				 <&gcc GCC_PCIE3_AUX_ARES>;

			reset-names = "pipe",
				      "sticky",
				      "axi_m",
				      "axi_s",
				      "axi_m_sticky",
				      "axi_s_sticky",
				      "ahb",
				      "aux";

			msi-parent = <&intc>;
			nvmem-cells = <&pcie3_disable>;

			pinctrl-0 = <&pcie3_default_state>;
			pinctrl-names = "default";

			phys = <&pcie3_lanes>;
			phy-names = "pciephy";

			perst-gpio = <&tlmm 42 GPIO_ACTIVE_LOW>;
			status = "disabled";
		};

		/* 2L controller */
		pcie2: pcie@50000000 {
			compatible = "qcom,pcie-ipq5424";
			reg =  <0x50000000 0xf1d>,
			       <0x50000f20 0xa8>,
			       <0x50001000 0x1000>,
			       <0xf0000 0x3000>,
			       <0x50100000 0x1000>;
			reg-names = "dbi", "elbi", "atu", "parf", "config";
			device_type = "pci";
			linux,pci-domain = <2>;
			bus-range = <0x00 0xff>;
			num-lanes = <2>;
			#address-cells = <3>;
			#size-cells = <2>;

			ranges = <0x81000000 0 0x50200000 0x50200000 0 0x00100000>,   /* downstream I/O */
				 <0x82000000 0 0x50300000 0x50300000 0 0x0fd00000>; /* non-prefetchable memory */

			#interrupt-cells = <1>;
			interrupt-map-mask = <0 0 0 0x7>;
			interrupt-map = <0 0 0 1 &intc 0 464 IRQ_TYPE_LEVEL_HIGH>, /* int_a */
					<0 0 0 2 &intc 0 465 IRQ_TYPE_LEVEL_HIGH>, /* int_b */
					<0 0 0 3 &intc 0 466 IRQ_TYPE_LEVEL_HIGH>, /* int_c */
					<0 0 0 4 &intc 0 467 IRQ_TYPE_LEVEL_HIGH>; /* int_d */

			interrupts = <GIC_SPI 463 IRQ_TYPE_LEVEL_HIGH>;
			interrupt-names = "global_irq";

			clocks = <&gcc GCC_PCIE2_AXI_M_CLK>,
				 <&gcc GCC_PCIE2_AXI_S_CLK>,
				 <&gcc GCC_PCIE2_AHB_CLK>,
				 <&gcc GCC_PCIE2_AUX_CLK>,
				 <&gcc GCC_PCIE2_AXI_S_BRIDGE_CLK>,
				 <&gcc GCC_PCIE2_RCHNG_CLK>;

			clock-names = "axi_m",
				      "axi_s",
				      "ahb",
				      "aux",
				      "axi_bridge",
				      "rchng";

			assigned-clocks = <&gcc GCC_PCIE2_AHB_CLK>,
					<&gcc GCC_PCIE2_AUX_CLK>,
					<&gcc GCC_PCIE2_AXI_M_CLK>,
					<&gcc GCC_PCIE2_AXI_S_BRIDGE_CLK>,
					<&gcc GCC_PCIE2_AXI_S_CLK>,
					<&gcc GCC_PCIE2_RCHNG_CLK>;

			assigned-clock-rates = <100000000>,
						<20000000>,
						<266666666>,
						<240000000>,
						<240000000>,
						<100000000>;

			resets = <&gcc GCC_PCIE2_PIPE_ARES>,
				 <&gcc GCC_PCIE2_CORE_STICKY_RESET>,
				 <&gcc GCC_PCIE2_AXI_M_ARES>,
				 <&gcc GCC_PCIE2_AXI_S_ARES>,
				 <&gcc GCC_PCIE2_AXI_M_STICKY_RESET>,
				 <&gcc GCC_PCIE2_AXI_S_STICKY_RESET>,
				 <&gcc GCC_PCIE2_AHB_ARES>,
				 <&gcc GCC_PCIE2_AUX_ARES>;

			reset-names = "pipe",
				      "sticky",
				      "axi_m",
				      "axi_s",
				      "axi_m_sticky",
				      "axi_s_sticky",
				      "ahb",
				      "aux";

			msi-parent = <&intc>;
			nvmem-cells = <&pcie2_disable>;

			pinctrl-0 = <&pcie2_default_state>;
			pinctrl-names = "default";

			phys = <&pcie2_lanes>;
			phy-names = "pciephy";

			perst-gpio = <&tlmm 41 GPIO_ACTIVE_LOW>;
			status = "disabled";
		};

		/* 1L controller */
		pcie1: pcie@60000000 {
			compatible = "qcom,pcie-ipq5424";
			reg =  <0x60000000 0xf1d>,
			       <0x60000f20 0xa8>,
			       <0x60001000 0x1000>,
			       <0x88000 0x3000>,
			       <0x60100000 0x1000>;
			reg-names = "dbi", "elbi", "atu", "parf", "config";
			device_type = "pci";
			linux,pci-domain = <1>;
			bus-range = <0x00 0xff>;
			num-lanes = <1>;
			#address-cells = <3>;
			#size-cells = <2>;

			ranges = <0x81000000 0 0x60200000 0x60200000 0 0x00100000>,   /* downstream I/O */
				 <0x82000000 0 0x60300000 0x60300000 0 0x0fd00000>; /* non-prefetchable memory */

			#interrupt-cells = <1>;
			interrupt-map-mask = <0 0 0 0x7>;
			interrupt-map = <0 0 0 1 &intc 0 449 IRQ_TYPE_LEVEL_HIGH>, /* int_a */
					<0 0 0 2 &intc 0 450 IRQ_TYPE_LEVEL_HIGH>, /* int_b */
					<0 0 0 3 &intc 0 451 IRQ_TYPE_LEVEL_HIGH>, /* int_c */
					<0 0 0 4 &intc 0 452 IRQ_TYPE_LEVEL_HIGH>; /* int_d */

			interrupts = <GIC_SPI 448 IRQ_TYPE_LEVEL_HIGH>;
			interrupt-names = "global_irq";

			clocks = <&gcc GCC_PCIE1_AXI_M_CLK>,
				 <&gcc GCC_PCIE1_AXI_S_CLK>,
				 <&gcc GCC_PCIE1_AHB_CLK>,
				 <&gcc GCC_PCIE1_AUX_CLK>,
				 <&gcc GCC_PCIE1_AXI_S_BRIDGE_CLK>,
				 <&gcc GCC_PCIE1_RCHNG_CLK>;

			clock-names = "axi_m",
				      "axi_s",
				      "ahb",
				      "aux",
				      "axi_bridge",
				      "rchng";

			assigned-clocks = <&gcc GCC_PCIE1_AHB_CLK>,
					<&gcc GCC_PCIE1_AUX_CLK>,
					<&gcc GCC_PCIE1_AXI_M_CLK>,
					<&gcc GCC_PCIE1_AXI_S_BRIDGE_CLK>,
					<&gcc GCC_PCIE1_AXI_S_CLK>,
					<&gcc GCC_PCIE1_RCHNG_CLK>;

			assigned-clock-rates = <100000000>,
						<20000000>,
						<240000000>,
						<240000000>,
						<240000000>,
						<100000000>;

			resets = <&gcc GCC_PCIE1_PIPE_ARES>,
				 <&gcc GCC_PCIE1_CORE_STICKY_RESET>,
				 <&gcc GCC_PCIE1_AXI_M_ARES>,
				 <&gcc GCC_PCIE1_AXI_S_ARES>,
				 <&gcc GCC_PCIE1_AXI_M_STICKY_RESET>,
				 <&gcc GCC_PCIE1_AXI_S_STICKY_RESET>,
				 <&gcc GCC_PCIE1_AHB_ARES>,
				 <&gcc GCC_PCIE1_AUX_ARES>;

			reset-names = "pipe",
				      "sticky",
				      "axi_m",
				      "axi_s",
				      "axi_m_sticky",
				      "axi_s_sticky",
				      "ahb",
				      "aux";

			msi-parent = <&intc>;
			nvmem-cells = <&pcie1_disable>;

			pinctrl-0 = <&pcie1_default_state>;
			pinctrl-names = "default";

			phys = <&pcie1_lanes>;
			phy-names = "pciephy";

			perst-gpio = <&tlmm 40 GPIO_ACTIVE_LOW>;
			status = "disabled";
		};

		/* 1L controller */
		pcie0: pcie@70000000 {
			compatible = "qcom,pcie-ipq5424";
			reg =  <0x70000000 0xf1d>,
			       <0x70000f20 0xa8>,
			       <0x70001000 0x1000>,
			       <0x80000 0x3000>,
			       <0x70100000 0x1000>;
			reg-names = "dbi", "elbi", "atu", "parf", "config";
			device_type = "pci";
			linux,pci-domain = <0>;
			bus-range = <0x00 0xff>;
			num-lanes = <1>;
			#address-cells = <3>;
			#size-cells = <2>;

			ranges = <0x81000000 0 0x70200000 0x70200000 0 0x00100000>,   /* downstream I/O */
				 <0x82000000 0 0x70300000 0x70300000 0 0x0fd00000>; /* non-prefetchable memory */

			#interrupt-cells = <1>;
			interrupt-map-mask = <0 0 0 0x7>;
			interrupt-map = <0 0 0 1 &intc 0 434 IRQ_TYPE_LEVEL_HIGH>, /* int_a */
					<0 0 0 2 &intc 0 435 IRQ_TYPE_LEVEL_HIGH>, /* int_b */
					<0 0 0 3 &intc 0 436 IRQ_TYPE_LEVEL_HIGH>, /* int_c */
					<0 0 0 4 &intc 0 437 IRQ_TYPE_LEVEL_HIGH>; /* int_d */

			interrupts = <GIC_SPI 433 IRQ_TYPE_LEVEL_HIGH>;
			interrupt-names = "global_irq";

			clocks = <&gcc GCC_PCIE0_AXI_M_CLK>,
				 <&gcc GCC_PCIE0_AXI_S_CLK>,
				 <&gcc GCC_PCIE0_AHB_CLK>,
				 <&gcc GCC_PCIE0_AUX_CLK>,
				 <&gcc GCC_PCIE0_AXI_S_BRIDGE_CLK>,
				 <&gcc GCC_PCIE0_RCHNG_CLK>;

			clock-names = "axi_m",
				      "axi_s",
				      "ahb",
				      "aux",
				      "axi_bridge",
				      "rchng";

			assigned-clocks = <&gcc GCC_PCIE0_AHB_CLK>,
					<&gcc GCC_PCIE0_AUX_CLK>,
					<&gcc GCC_PCIE0_AXI_M_CLK>,
					<&gcc GCC_PCIE0_AXI_S_BRIDGE_CLK>,
					<&gcc GCC_PCIE0_AXI_S_CLK>,
					<&gcc GCC_PCIE0_RCHNG_CLK>;

			assigned-clock-rates = <100000000>,
						<20000000>,
						<240000000>,
						<240000000>,
						<240000000>,
						<100000000>;

			resets = <&gcc GCC_PCIE0_PIPE_ARES>,
				 <&gcc GCC_PCIE0_CORE_STICKY_RESET>,
				 <&gcc GCC_PCIE0_AXI_M_ARES>,
				 <&gcc GCC_PCIE0_AXI_S_ARES>,
				 <&gcc GCC_PCIE0_AXI_M_STICKY_RESET>,
				 <&gcc GCC_PCIE0_AXI_S_STICKY_RESET>,
				 <&gcc GCC_PCIE0_AHB_ARES>,
				 <&gcc GCC_PCIE0_AUX_ARES>;

			reset-names = "pipe",
				      "sticky",
				      "axi_m",
				      "axi_s",
				      "axi_m_sticky",
				      "axi_s_sticky",
				      "ahb",
				      "aux";

			msi-parent = <&intc>;
			nvmem-cells = <&pcie0_disable>;

			pinctrl-0 = <&pcie0_default_state>;
			pinctrl-names = "default";

			phys = <&pcie0_lanes>;
			phy-names = "pciephy";

			perst-gpio = <&tlmm 39 GPIO_ACTIVE_LOW>;
			status = "disabled";
		};

		wifi0: wifi@c0000000 {
			compatible = "qcom,cnss-qca5424", "qcom,ipq5424-wifi";
			reg = <0xc000000 0x1000000>;
			qcom,tgt-mem-mode = <0>;
			qcom,rproc = <&q6v5_wcss>;
			qcom,bdf-addr = <0x4B500000 0x4B500000 0x4B500000
					 0x0 0x0 0x0>;
			qcom,caldb-addr = <0x4CE00000 0x4CE00000 0x0
					   0x0 0x0 0x0>;
			qcom,caldb-size = <0x500000>;
			interrupts = <0 559 1>, /* misc-pulse1 */
				<0 560 1>, /* misc-latch */
				<0 561 1>, /* sw-exception */
				<0 518 1>, /* ce0 */
				<0 519 1>, /* ce1 */
				<0 520 1>, /* ce2 */
				<0 521 1>, /* ce3 */
				<0 522 1>, /* ce4 */
				<0 523 1>, /* ce5 */
				<0 524 1>, /* ce6 */
				<0 525 1>, /* ce7 */
				<0 526 1>, /* ce8 */
				<0 527 1>, /* ce9 */
				<0 528 1>, /* ce10 */
				<0 529 1>, /* ce11 */
				<0 574 1>, /* host2wbm-desc-feed */
				<0 578 1>, /* host2reo-re-injection */
				<0 576 1>, /* host2reo-command */
				<0 627 1>, /* host2rxdma-monitor-ring1 */
				<0 540 1>, /* reo2ost-exception */
				<0 549 1>, /* wbm2host-rx-release */
				<0 580 1>, /* reo2host-status */
				<0 537 1>, /* reo2host-destination-ring4 */
				<0 536 1>, /* reo2host-destination-ring3 */
				<0 535 1>, /* reo2host-destination-ring2 */
				<0 534 1>, /* reo2host-destination-ring1 */
				<0 571 1>, /* rxdma2host-monitor-destination-mac3 */
				<0 571 1>, /* rxdma2host-monitor-destination-mac2 */
				<0 567 1>, /* rxdma2host-monitor-destination-mac1 */
				<0 637 1>, /* host2rxdma-host-buf-ring-mac3 */
				<0 637 1>, /* host2rxdma-host-buf-ring-mac2 */
				<0 632 1>, /* host2rxdma-host-buf-ring-mac1 */
				<0 590 1>, /* host2tcl-input-ring4 */
				<0 583 1>, /* host2tcl-input-ring3 */
				<0 582 1>, /* host2tcl-input-ring2 */
				<0 581 1>, /* host2tcl-input-ring1 */
				<0 533 1>, /* wbm2host-tx-completions-ring4 */
				<0 532 1>, /* wbm2host-tx-completions-ring3 */
				<0 531 1>, /* wbm2host-tx-completions-ring2 */
				<0 530 1>, /* wbm2host-tx-completions-ring1 */
				<0 626 1>, /* host2tx-monitor-ring1 */
				<0 569 1>, /* txmon2host-monitor-destination-mac3 */
				<0 569 1>, /* txmon2host-monitor-destination-mac2 */
				<0 565 1>, /* txmon2host-monitor-destination-mac1 */
				<0 502 1>, /* umac_reset */
				/* Unused Interrupts */
				<0 558 1>, /* host2rxdma-monitor-ring3 */
				<0 558 1>, /* host2rxdma-monitor-ring2 */
				<0 558 1>, /* ppdu-end-interrupts-mac3 */
				<0 558 1>, /* ppdu-end-interrupts-mac2 */
				<0 558 1>, /* ppdu-end-interrupts-mac1 */
				<0 558 1>, /* rxdma2host-monitor-status-ring-mac3 */
				<0 558 1>, /* rxdma2host-monitor-status-ring-mac2 */
				<0 558 1>, /* rxdma2host-monitor-status-ring-mac1 */
				<0 558 1>, /* rxdma2host-destination-ring-mac3 */
				<0 558 1>, /* rxdma2host-destination-ring-mac2 */
				<0 558 1>, /* rxdma2host-destination-ring-mac1 */
				<0 608 1>, /* reo2ppe1 */
				<0 586 1>, /* reo2ppe */
				<0 573 1>, /* ppe_wbm_rel */
				<0 562 1>; /* ppe2tcl */

			interrupt-names = "misc-pulse1",
				"misc-latch",
				"sw-exception",
				"ce0",
				"ce1",
				"ce2",
				"ce3",
				"ce4",
				"ce5",
				"ce6",
				"ce7",
				"ce8",
				"ce9",
				"ce10",
				"ce11",
				"host2wbm-desc-feed",
				"host2reo-re-injection",
				"host2reo-command",
				"host2rxdma-monitor-ring1",
				"reo2ost-exception",
				"wbm2host-rx-release",
				"reo2host-status",
				"reo2host-destination-ring4",
				"reo2host-destination-ring3",
				"reo2host-destination-ring2",
				"reo2host-destination-ring1",
				"rxdma2host-monitor-destination-mac3",
				"rxdma2host-monitor-destination-mac2",
				"rxdma2host-monitor-destination-mac1",
				"host2rxdma-host-buf-ring-mac3",
				"host2rxdma-host-buf-ring-mac2",
				"host2rxdma-host-buf-ring-mac1",
				"host2tcl-input-ring4",
				"host2tcl-input-ring3",
				"host2tcl-input-ring2",
				"host2tcl-input-ring1",
				"wbm2host-tx-completions-ring4",
				"wbm2host-tx-completions-ring3",
				"wbm2host-tx-completions-ring2",
				"wbm2host-tx-completions-ring1",
				"host2tx-monitor-ring1",
				"txmon2host-monitor-destination-mac3",
				"txmon2host-monitor-destination-mac2",
				"txmon2host-monitor-destination-mac1",
				"umac_reset",
				/* Unused Interrupts */
				"host2rxdma-monitor-ring3",
				"host2rxdma-monitor-ring2",
				"ppdu-end-interrupts-mac3",
				"ppdu-end-interrupts-mac2",
				"ppdu-end-interrupts-mac1",
				"rxdma2host-monitor-status-ring-mac3",
				"rxdma2host-monitor-status-ring-mac2",
				"rxdma2host-monitor-status-ring-mac1",
				"rxdma2host-destination-ring-mac3",
				"rxdma2host-destination-ring-mac2",
				"rxdma2host-destination-ring-mac1",
				"reo2ppe1",
				"reo2ppe",
				"ppe_wbm_rel",
				"ppe2tcl";
			/* 36 indicates GPIO number for LED_2G.
			 * 0 indicates that the GPIO is active high.
			 */
			led-gpio = <&tlmm 36 0>;
			qcom,pta-num = <0>;
			qcom,coex-mode = <0x2>;
			qcom,bt-active-time = <0x18>;
			qcom,bt-priority-time = <0x12>;
			qcom,coex-algo = <0x2>;
			qcom,pta-priority = <0x80800505>;
			status = "disabled";
		};

		stm: stm@6002000 {
			compatible = "arm,coresight-stm", "arm,primecell";
			reg = <0x06002000 0x1000>,
				<0x09000000 0x01000000>;
			reg-names = "stm-base", "stm-stimulus-base";
			coresight-name = "coresight-stm";
			clocks = <&gcc GCC_QDSS_DAP_CLK>,
				 <&gcc GCC_QDSS_AT_CLK>;
			clock-names = "apb_pclk", "atclk";

			out-ports {
				port {
					stm_out: endpoint {
						remote-endpoint = <&funnel0_in7>;
					};
				};
			};
		};

		funnel_in0: funnel@6041000 {
			compatible = "arm,coresight-dynamic-funnel", "arm,primecell";
			reg = <0x6041000 0x1000>;
			reg-names = "funnel-base";
			coresight-name = "coresight-funnel-in0";
			clocks = <&gcc GCC_QDSS_DAP_CLK>,
				 <&gcc GCC_QDSS_AT_CLK>;
			clock-names = "apb_pclk", "atclk";

			in-ports {
				#address-cells = <1>;
				#size-cells = <0>;

				/*
				 * Port 0 - TME
				 * Port 2 - SNOC
				 * Port 3 - NSS
				 * Port 4 - CNOC
				 * Port 5 - MEMNOC
				 * Port 6 - TPDA QDSS
				 */

				port@7 {
					reg = <7>;
					funnel0_in7: endpoint {
						remote-endpoint = <&stm_out>;
					};
				};
			};

			out-ports {
				port {
					funnel0_out: endpoint {
						remote-endpoint = <&merge_funnel_in0>;
					};
				};
			};
		};

		funnel_in1: funnel@6042000 {
			compatible = "arm,coresight-dynamic-funnel", "arm,primecell";
			reg = <0x06042000 0x1000>;
			reg-names = "funnel-base";
			coresight-name = "coresight-funnel-in1";
			clocks = <&gcc GCC_QDSS_DAP_CLK>,
				 <&gcc GCC_QDSS_AT_CLK>;
			clock-names = "apb_pclk", "atclk";

			in-ports {
				#address-cells = <1>;
				#size-cells = <0>;

				/*
				 * Port 0 - AGGRENOC
				 * Port 1 - WCSS Q6
				 * Port 3 - TPDA QDSS
				 * Port 5 - WCSS Core
				 */

				port@2 {
					reg = <4>;
					funnel1_in2: endpoint {
						remote-endpoint = <&apss_funnel_out>;
					};
				};
			};

			out-ports {
				port {
					funnel1_out: endpoint {
						remote-endpoint = <&merge_funnel_in1>;
					};
				};
			};

		};

		funnel_merge: funnel@6045000 {
			compatible = "arm,coresight-dynamic-funnel", "arm,primecell";
			reg = <0x06045000 0x1000>;
			reg-names = "funnel-base";
			coresight-name = "coresight-funnel-merge";
			clocks = <&gcc GCC_QDSS_DAP_CLK>,
				 <&gcc GCC_QDSS_AT_CLK>;
			clock-names = "apb_pclk", "atclk";

			out-ports {
				port {
					merge_funnel_out: endpoint {
						remote-endpoint = <&etf_in>;
					};
				};
			};

			in-ports {
				#address-cells = <1>;
				#size-cells = <0>;

				port@0 {
					reg = <0>;
					merge_funnel_in0: endpoint {
						remote-endpoint = <&funnel0_out>;
					};
				};

				port@1 {
					reg = <1>;
					merge_funnel_in1: endpoint {
						remote-endpoint = <&funnel1_out>;
					};
				};
			};

		};

		etr_replicator: replicator@6046000 {
			compatible = "arm,coresight-dynamic-replicator", "arm,primecell";
			reg = <0x06046000 0x1000>;
			reg-names = "replicator-base";
			coresight-name = "coresight-replicator";
			clocks = <&gcc GCC_QDSS_DAP_CLK>,
				 <&gcc GCC_QDSS_AT_CLK>;
			clock-names = "apb_pclk", "atclk";

			out-ports {
				#address-cells = <1>;
				#size-cells = <0>;

				port@0 {
					reg = <0>;
					etr_replicator_out0: endpoint {
						remote-endpoint = <&etr_in>;
					};
				};
			};

			in-ports {
				port {
					etr_replicator_in0: endpoint {
						remote-endpoint = <&etf_out>;
					};
				};
			};
		};

		etf@6047000 {
			compatible = "arm,coresight-tmc", "arm,primecell";
			reg = <0x06047000 0x1000>;
			reg-names = "tmc-base";
			coresight-name = "coresight-tmc-etf";
			arm,default-sink;
			clocks = <&gcc GCC_QDSS_DAP_CLK>;
			clock-names = "apb_pclk";

			out-ports {
				port {
					etf_out: endpoint {
						remote-endpoint = <&etr_replicator_in0>;
					};
				};
			};

			in-ports {
				port {
					etf_in: endpoint {
						remote-endpoint = <&merge_funnel_out>;
					};
				};
			};
		};

		tmc_etr: tmc@6048000 {
			compatible = "arm,coresight-tmc", "arm,primecell";
			reg = <0x06048000 0x1000>;
			reg-names = "tmc-base";
			interrupts = <GIC_SPI 166 IRQ_TYPE_EDGE_RISING>;
			interrupt-names = "byte-cntr-irq";
			arm,buffer-size = <0x100000>;
			arm,scatter-gather;
			memory-region = <&tmc_etr_region>;
			coresight-name = "coresight-tmc-etr";
			clocks = <&gcc GCC_QDSS_DAP_CLK>;
			clock-names = "apb_pclk";

			in-ports {
				port {
					etr_in: endpoint {
						remote-endpoint = <&etr_replicator_out0>;
					};
				};
			};
		};

		etm0: etm@6480000 {
			compatible = "arm,coresight-etm4x", "arm,primecell";
			reg = <0x6480000 0x1000>;
			coresight-name = "coresight-etm0";
			cpu = <&CPU0>;
			clocks = <&gcc GCC_QDSS_DAP_CLK>;
			clock-names = "apb_pclk";

			out-ports {
				port {
					etm0_out: endpoint {
						remote-endpoint = <&apss_funnel_in0>;
					};
				};
			};
		};

		etm1: etm@6580000 {
			compatible = "arm,coresight-etm4x", "arm,primecell";
			reg = <0x6580000 0x1000>;
			coresight-name = "coresight-etm1";
			cpu = <&CPU1>;
			clocks = <&gcc GCC_QDSS_DAP_CLK>;
			clock-names = "apb_pclk";

			out-ports {
				port {
					etm1_out: endpoint {
						remote-endpoint = <&apss_funnel_in1>;
					};
				};
			};
		};

		etm2: etm@6680000 {
			compatible = "arm,coresight-etm4x", "arm,primecell";
			reg = <0x6680000 0x1000>;
			coresight-name = "coresight-etm2";
			cpu = <&CPU2>;
			clocks = <&gcc GCC_QDSS_DAP_CLK>;
			clock-names = "apb_pclk";

			out-ports {
				port {
					etm2_out: endpoint {
						remote-endpoint = <&apss_funnel_in2>;
					};
				};
			};
		};

		etm3: etm@6780000 {
			compatible = "arm,coresight-etm4x", "arm,primecell";
			reg = <0x6780000 0x1000>;
			coresight-name = "coresight-etm3";
			cpu = <&CPU3>;
			clocks = <&gcc GCC_QDSS_DAP_CLK>;
			clock-names = "apb_pclk";

			out-ports {
				port {
					etm3_out: endpoint {
						remote-endpoint = <&apss_funnel_in3>;
					};
				};
			};
		};

		funnel_apss: funnel@6781000 {
			compatible = "arm,coresight-dynamic-funnel", "arm,primecell";
			reg = <0x6781000 0x1000>;
			reg-names = "funnel-base";
			coresight-name = "coresight-funnel-apss";
			clocks = <&gcc GCC_QDSS_DAP_CLK>,
				 <&gcc GCC_QDSS_AT_CLK>;
			clock-names = "apb_pclk", "atclk";

			out-ports {
				port {
					apss_funnel_out: endpoint {
						remote-endpoint = <&funnel1_in2>;
					};
				};
			};

			in-ports {
				#address-cells = <1>;
				#size-cells = <0>;

				port@0 {
					reg = <0>;
					apss_funnel_in0: endpoint {
						remote-endpoint = <&etm0_out>;
					};
				};

				port@1 {
					reg = <1>;
					apss_funnel_in1: endpoint {
						remote-endpoint = <&etm1_out>;
					};
				};

				port@2 {
					reg = <2>;
					apss_funnel_in2: endpoint {
						remote-endpoint = <&etm2_out>;
					};
				};

				port@3 {
					reg = <3>;
					apss_funnel_in3: endpoint {
						remote-endpoint = <&etm3_out>;
					};
				};
			};
		};

		sram@8600000 {
			compatible = "qcom,ipq5424-imem", "syscon", "simple-mfd";
			reg = <0x08600000 0x1000>;
			ranges = <0 0x08600000 0x1000>;

			#address-cells = <1>;
			#size-cells = <1>;

			tz-log-buf-addr@720 {
				compatible = "qcom,msm-imem-tz-log-buf-addr";
				reg = <0x720 4>;
			};

			restart-reason-buf-addr@7b0 {
				compatible = "qcom,msm-imem-restart-reason-buf-addr";
				reg = <0x7b0 4>;
			};

			restart-reason-buf-q6-addr@7b4 {
				compatible = "qcom,imem-restart-reason-buf-q6-addr";
				reg = <0x7b4 4>;
			};

			restart-reason-buf-wr-addr@7ac {
				compatible = "qcom,imem-restart-reason-buf-wr-addr";
				reg = <0x7ac 4>;
			};
		};

		qusb_phy_1: phy@71000 {
			compatible = "qcom,ipq5424-qusb2-phy";
			reg = <0x071000 0x180>;
			#phy-cells = <0>;

			clocks = <&gcc GCC_USB1_PHY_CFG_AHB_CLK>,
				<&xo>;
			clock-names = "cfg_ahb", "ref";

			resets = <&gcc GCC_QUSB2_1_PHY_BCR>;
			status = "disabled";
		};

		usb2: usb2@1e00000 {
			compatible = "qcom,ipq5424-dwc3", "qcom,dwc3";
			reg = <0x1ef8800 0x400>;
			#address-cells = <1>;
			#size-cells = <1>;
			ranges;

			clocks = <&gcc GCC_USB1_MASTER_CLK>,
				 <&gcc GCC_USB1_SLEEP_CLK>,
				 <&gcc GCC_USB1_MOCK_UTMI_CLK>,
				 <&gcc GCC_USB1_PHY_CFG_AHB_CLK>,
				 <&gcc GCC_CNOC_USB_CLK>;

			clock-names = "master",
				      "sleep",
				      "mock_utmi",
				      "cfg_ahb_clk",
				      "cnoc_usb_clk";

			assigned-clocks = <&gcc GCC_USB1_MASTER_CLK>,
					  <&gcc GCC_USB1_MOCK_UTMI_CLK>;
			assigned-clock-rates = <200000000>,
					       <24000000>;

			resets = <&gcc GCC_USB1_BCR>;
			qcom,select-utmi-as-pipe-clk;
			status = "disabled";

			dwc_1: dwc3@1e00000 {
				compatible = "snps,dwc3";
				reg = <0x1e00000 0xe000>;
				clocks = <&gcc GCC_USB1_MOCK_UTMI_CLK>;
				clock-names = "ref";
				interrupts = <GIC_SPI 396 IRQ_TYPE_LEVEL_HIGH>;
				phys = <&qusb_phy_1>;
				phy-names = "usb2-phy";
				tx-fifo-resize;
				snps,is-utmi-l1-suspend;
				snps,hird-threshold = /bits/ 8 <0x0>;
				snps,dis_u2_susphy_quirk;
				snps,dis_u3_susphy_quirk;
				maximum-speed = "high-speed";
				dr_mode = "host";
			};
		};

		qusb_phy_0: phy@7b000 {
			compatible = "qcom,ipq5424-qusb2-phy";
			reg = <0x07b000 0x180>;
			#phy-cells = <0>;

			clocks = <&gcc GCC_USB0_PHY_CFG_AHB_CLK>,
				<&xo>;
			clock-names = "cfg_ahb", "ref";

			resets = <&gcc GCC_QUSB2_0_PHY_BCR>;
			status = "disabled";
		};

		ssphy_0: phy@7d000 {
			compatible = "qcom,ipq5424-qmp-usb3-phy";
			reg = <0x0007d000 0xa00>;
			#phy-cells = <0>;

			clocks = <&gcc GCC_USB0_AUX_CLK>,
				 <&xo>,
				 <&gcc GCC_USB0_PHY_CFG_AHB_CLK>,
				 <&gcc GCC_USB0_PIPE_CLK>;
			clock-names = "aux",
				      "ref",
				      "cfg_ahb",
				      "pipe";

			resets = <&gcc GCC_USB0_PHY_BCR>,
				 <&gcc GCC_USB3PHY_0_PHY_BCR>;
			reset-names = "phy",
				      "phy_phy";

			#clock-cells = <0>;
			clock-output-names = "usb0_pipe_clk";

			status = "disabled";
		};

		usb3: usb3@8a00000 {
			compatible = "qcom,ipq5424-dwc3", "qcom,dwc3";
			reg = <0x8af8800 0x400>;
			#address-cells = <1>;
			#size-cells = <1>;
			ranges;

			clocks = <&gcc GCC_USB0_MASTER_CLK>,
				<&gcc GCC_USB0_SLEEP_CLK>,
				<&gcc GCC_USB0_MOCK_UTMI_CLK>,
				<&gcc GCC_USB0_PHY_CFG_AHB_CLK>,
				<&gcc GCC_USB0_AUX_CLK>,
				<&gcc GCC_USB0_PIPE_CLK>;

			clock-names = "master",
				"sleep",
				"mock_utmi",
				"cfg_ahb_clk",
				"aux_clk",
				"pipe_clk";

			assigned-clocks = <&gcc GCC_USB0_MASTER_CLK>,
					  <&gcc GCC_USB0_MOCK_UTMI_CLK>;
			assigned-clock-rates = <200000000>,
					       <24000000>;

			resets = <&gcc GCC_USB_BCR>;
			status = "disabled";

			dwc_0: dwc3@8a00000 {
				compatible = "snps,dwc3";
				reg = <0x8a00000 0xcd00>;
				clocks = <&gcc GCC_USB0_MOCK_UTMI_CLK>;
				clock-names = "ref";
				interrupts = <GIC_SPI 409 IRQ_TYPE_LEVEL_HIGH>;
				phys = <&qusb_phy_0>, <&ssphy_0>;
				phy-names = "usb2-phy", "usb3-phy";
				tx-fifo-resize;
				snps,is-utmi-l1-suspend;
				snps,hird-threshold = /bits/ 8 <0x0>;
				snps,dis_u2_susphy_quirk;
				snps,dis_u3_susphy_quirk;
				dr_mode = "host";
			};
		};
	};

	timer {
		compatible = "arm,armv8-timer";
		interrupts = <GIC_PPI 13 (GIC_CPU_MASK_SIMPLE(4) | IRQ_TYPE_LEVEL_LOW)>,
			     <GIC_PPI 14 (GIC_CPU_MASK_SIMPLE(4) | IRQ_TYPE_LEVEL_LOW)>,
			     <GIC_PPI 11 (GIC_CPU_MASK_SIMPLE(4) | IRQ_TYPE_LEVEL_LOW)>,
			     <GIC_PPI 10 (GIC_CPU_MASK_SIMPLE(4) | IRQ_TYPE_LEVEL_LOW)>,
			     <GIC_PPI 12 (GIC_CPU_MASK_SIMPLE(4) | IRQ_TYPE_LEVEL_LOW)>;
	};

	qcom,test@0 {
		compatible = "qcom,testmhi";
		qcom,wlan-ramdump-dynamic = <0x600000>;
	};

	wcss: wcss-smp2p {
		compatible = "qcom,smp2p";
		qcom,smem = <435>, <428>;

		interrupt-parent = <&intc>;
		interrupts = <GIC_SPI 501 IRQ_TYPE_EDGE_RISING>;

		mboxes = <&apcs_glb 9>;

		qcom,local-pid = <0>;
		qcom,remote-pid = <1>;

		wcss_smp2p_out: master-kernel {
			qcom,entry-name = "master-kernel";
			#qcom,smem-state-cells = <1>;
		};

		wcss_smp2p_in: slave-kernel {
			qcom,entry-name = "slave-kernel";
			interrupt-controller;
			#interrupt-cells = <2>;
		};
	};

	ipq-debug {
		compatible = "qcom,ipq-debug-ipq5424";
		qcom,rproc = <&q6v5_wcss>;
	};

	thermal_zones: thermal-zones {
		cpu0-thermal {
			polling-delay-passive = <0>;
			polling-delay = <0>;
			thermal-sensors = <&tsens 14>;

			trips {
				cpu-critical {
					temperature = <120000>;
					hysteresis = <9000>;
					type = "critical";
				};

				cpu0_thermal_alert: cpu-passive {
					temperature = <110000>;
					hysteresis = <9000>;
					type = "passive";
				};
			};

			cooling-maps {
				map0 {
					trip = <&cpu0_thermal_alert>;
					/* Set maximum frequency as 1.4164 MHz  */
					cooling-device = <&CPU0 1 1>,
							 <&CPU1 1 1>,
							 <&CPU2 1 1>,
							 <&CPU3 1 1>;
				};
			};
		};

		cpu1-thermal {
			polling-delay-passive = <0>;
			polling-delay = <0>;
			thermal-sensors = <&tsens 12>;

			trips {
				cpu-critical {
					temperature = <120000>;
					hysteresis = <9000>;
					type = "critical";
				};

				cpu-passive {
					temperature = <110000>;
					hysteresis = <9000>;
					type = "passive";
				};
			};
		};

		cpu2-thermal {
			polling-delay-passive = <0>;
			polling-delay = <0>;
			thermal-sensors = <&tsens 11>;

			trips {
				cpu-critical {
					temperature = <120000>;
					hysteresis = <9000>;
					type = "critical";
				};

				cpu-passive {
					temperature = <110000>;
					hysteresis = <9000>;
					type = "passive";
				};
			};
		};

		cpu3-thermal {
			polling-delay-passive = <0>;
			polling-delay = <0>;
			thermal-sensors = <&tsens 13>;

			trips {
				cpu-critical {
					temperature = <120000>;
					hysteresis = <9000>;
					type = "critical";
				};

				cpu-passive {
					temperature = <110000>;
					hysteresis = <9000>;
					type = "passive";
				};
			};
		};

		wcss-tile2-thermal {
			polling-delay-passive = <0>;
			polling-delay = <0>;
			thermal-sensors = <&tsens 9>;

			trips {
				wcss_tile2-critical {
					temperature = <125000>;
					hysteresis = <9000>;
					type = "critical";
				};
			};
		};

		wcss-tile3-thermal {
			polling-delay-passive = <0>;
			polling-delay = <0>;
			thermal-sensors = <&tsens 10>;

			trips {
				wcss_tile3-critical {
					temperature = <125000>;
					hysteresis = <9000>;
					type = "critical";
				};
			};
		};

		top-glue-thermal {
			polling-delay-passive = <0>;
			polling-delay = <0>;
			thermal-sensors = <&tsens 15>;

			trips {
				top-glue-critical {
					temperature = <125000>;
					hysteresis = <9000>;
					type = "critical";
				};
			};
		};
	};
};

#ifndef __CPU_THERMAL__
#include "ipq5424-thermald.dtsi"
#endif
